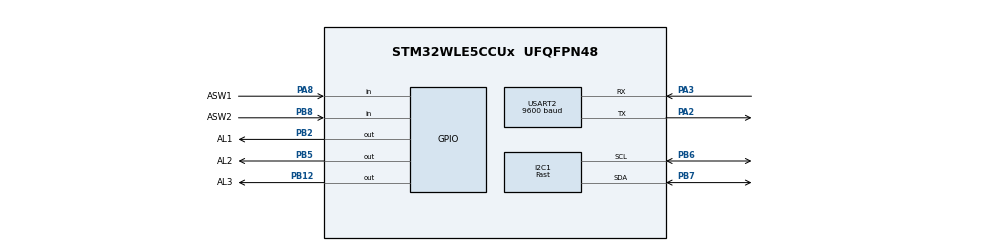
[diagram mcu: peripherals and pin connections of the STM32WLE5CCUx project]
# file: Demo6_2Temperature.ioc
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I2C1.I2C_Fall_Time=0
I2C1.I2C_Rise_Time=0
I2C1.I2C_Speed_Mode=I2C_Fast
I2C1.Speed=400
I2C1.Timing=0x2010091A
Mcu.Family=STM32WL
Mcu.Name=STM32WLE5CCUx
Mcu.Package=UFQFPN48
NVIC.PriorityGroup=NVIC_PRIORITYGROUP_2
NVIC.USART2_IRQn=true\:1\:0\:true\:false\:true\:true\:true\:true
PA13.Mode=Serial_Wire
PA13.Signal=DEBUG_JTMS-SWDIO
PA14.Mode=Serial_Wire
PA14.Signal=DEBUG_JTCK-SWCLK
PA2.Mode=Asynchronous
PA2.Signal=USART2_TX
PA3.Mode=Asynchronous
PA3.Signal=USART2_RX
PA8.GPIO_Label=ASW1
PA8.GPIO_PuPd=GPIO_PULLUP
PA8.Signal=GPIO_Input
PB12.GPIO_Label=AL3
PB12.PinState=GPIO_PIN_SET
PB12.Signal=GPIO_Output
PB2.GPIO_Label=AL1
PB2.PinState=GPIO_PIN_SET
PB2.Signal=GPIO_Output
PB5.GPIO_Label=AL2
PB5.PinState=GPIO_PIN_SET
PB5.Signal=GPIO_Output
PB6.GPIO_FM6=__NULL
PB6.GPIO_Pu=GPIO_NOPULL
PB6.GPIO_Speed=GPIO_SPEED_FREQ_LOW
PB6.Mode=I2C
PB6.Signal=I2C1_SCL
PB7.GPIO_FM7=__NULL
PB7.GPIO_Pu=GPIO_NOPULL
PB7.GPIO_Speed=GPIO_SPEED_FREQ_LOW
PB7.Mode=I2C
PB7.Signal=I2C1_SDA
PB8.GPIO_Label=ASW2
PB8.GPIO_PuPd=GPIO_PULLUP
PB8.Signal=GPIO_Input
ProjectManager.HeapSize=0x200
ProjectManager.StackSize=0x400
ProjectManager.TargetToolchain=MDK-ARM V5.37
RCC.AHBFreq_Value=48000000
RCC.APB1Freq_Value=48000000
RCC.APB1TimFreq_Value=48000000
RCC.APB2Freq_Value=48000000
RCC.APB2TimFreq_Value=48000000
RCC.APB3Freq_Value=48000000
RCC.CortexFreq_Value=48000000
RCC.HCLKFreq_Value=48000000
RCC.HSE_VALUE=8000000
RCC.HSI_VALUE=16000000
RCC.LSE_VALUE=32768
RCC.MSIClockRange=RCC_MSIRANGE_11
RCC.SYSCLKFreq_VALUE=48000000
RCC.VCOOutputFreq_Value=384000000
USART2.BaudRate=9600
USART2.VirtualMode-Asynchronous=VM_ASYNC
board=custom

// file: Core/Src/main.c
/* USER CODE BEGIN Header */
/**
  ******************************************************************************
  * @file           : main.c
  * @brief          : Main program body
  ******************************************************************************
  * @attention
  *
  * Copyright (c) 2024 STMicroelectronics.
  * All rights reserved.
  *
  * This software is licensed under terms that can be found in the LICENSE file
  * in the root directory of this software component.
  * If no LICENSE file comes with this software, it is provided AS-IS.
  *
  ******************************************************************************
  */
/* USER CODE END Header */
#include "main.h"
#include "i2c.h"
#include "usart.h"
#include "gpio.h"

/* USER CODE BEGIN Includes */
#include "task.h"
/* USER CODE END Includes */

void SystemClock_Config(void);

int main(void)
{

    /* MCU Configuration--------------------------------------------------------*/

    /* Reset of all peripherals, Initializes the Flash interface and the Systick. */
    HAL_Init();

    /* Configure the system clock */
    SystemClock_Config();

    /* Initialize all configured peripherals */
    MX_GPIO_Init();
    MX_I2C1_Init();
    MX_USART2_UART_Init();
    /* USER CODE BEGIN 2 */
    BSP_Init();
    /* USER CODE END 2 */

    /* Infinite loop */
    /* USER CODE BEGIN WHILE */
    while (1)
    {
        OLED_Proc();
        KEY_Proc();
        /* USER CODE END WHILE */

    }
}

void SystemClock_Config(void)
{
    RCC_OscInitTypeDef RCC_OscInitStruct = {0};
    RCC_ClkInitTypeDef RCC_ClkInitStruct = {0};

    /** Configure the main internal regulator output voltage
    */
    __HAL_PWR_VOLTAGESCALING_CONFIG(PWR_REGULATOR_VOLTAGE_SCALE1);

    /** Initializes the CPU, AHB and APB buses clocks
    */
    RCC_OscInitStruct.OscillatorType = RCC_OSCILLATORTYPE_MSI;
    RCC_OscInitStruct.MSIState = RCC_MSI_ON;
    RCC_OscInitStruct.MSICalibrationValue = RCC_MSICALIBRATION_DEFAULT;
    RCC_OscInitStruct.MSIClockRange = RCC_MSIRANGE_11;
    RCC_OscInitStruct.PLL.PLLState = RCC_PLL_NONE;
    if (HAL_RCC_OscConfig(&RCC_OscInitStruct) != HAL_OK)
    {
        Error_Handler();
    }

    /** Configure the SYSCLKSource, HCLK, PCLK1 and PCLK2 clocks dividers
    */
    RCC_ClkInitStruct.ClockType = RCC_CLOCKTYPE_HCLK3 | RCC_CLOCKTYPE_HCLK
                                  | RCC_CLOCKTYPE_SYSCLK | RCC_CLOCKTYPE_PCLK1
                                  | RCC_CLOCKTYPE_PCLK2;
    RCC_ClkInitStruct.SYSCLKSource = RCC_SYSCLKSOURCE_MSI;
    RCC_ClkInitStruct.AHBCLKDivider = RCC_SYSCLK_DIV1;
    RCC_ClkInitStruct.APB1CLKDivider = RCC_HCLK_DIV1;
    RCC_ClkInitStruct.APB2CLKDivider = RCC_HCLK_DIV1;
    RCC_ClkInitStruct.AHBCLK3Divider = RCC_SYSCLK_DIV1;

    if (HAL_RCC_ClockConfig(&RCC_ClkInitStruct, FLASH_LATENCY_2) != HAL_OK)
    {
        Error_Handler();
    }
}

void Error_Handler(void)
{
    __disable_irq();
    while (1)
    {
    }
}
